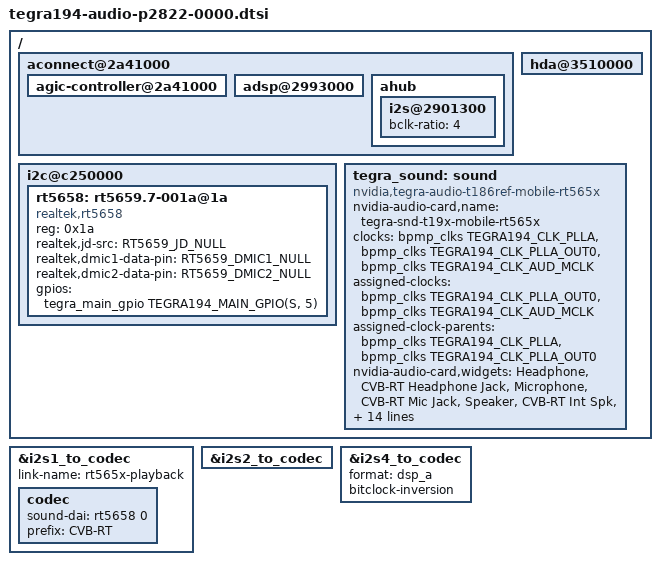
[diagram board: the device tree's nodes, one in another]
/*
 * Copyright (c) 2017-2020, NVIDIA CORPORATION.  All rights reserved.
 *
 * This program is free software; you can redistribute it and/or modify it
 * under the terms and conditions of the GNU General Public License,
 * version 2, as published by the Free Software Foundation.
 *
 * This program is distributed in the hope it will be useful, but WITHOUT
 * ANY WARRANTY; without even the implied warranty of MERCHANTABILITY or
 * FITNESS FOR A PARTICULAR PURPOSE.  See the GNU General Public License for
 * more details.
 *
 * You should have received a copy of the GNU General Public License
 * along with this program.  If not, see <http://www.gnu.org/licenses/>.
 */

/*
 * T194 p2822-0000 audio common DTSI file.
 */

#include <audio/tegra-platforms-audio-dai-links.dtsi>
#include <audio/tegra186-audio-dai-links.dtsi>
#include <dt-bindings/gpio/tegra194-gpio.h>
#include <dt-bindings/sound/rt5659.h>

/ {

	aconnect@2a41000 {
		status = "okay";

		agic-controller@2a41000 {
			status = "okay";
		};

		adsp@2993000 {
			status = "okay";
		};
	};

	i2c@c250000 {
		rt5658: rt5659.7-001a@1a {
			compatible = "realtek,rt5658";
			reg = <0x1a>;

			realtek,jd-src = <RT5659_JD_NULL>;
			realtek,dmic1-data-pin = <RT5659_DMIC1_NULL>;
			realtek,dmic2-data-pin = <RT5659_DMIC2_NULL>;

			gpios = <&tegra_main_gpio TEGRA194_MAIN_GPIO(S, 5) 0>;
			#sound-dai-cells = <1>;

			status = "okay";
		};
	};

	/* Default for all I2S is long fsync width(31) */
	aconnect@2a41000 {
		ahub {
			/* I2S4 in Short frame sync for BT SCO */
			i2s@2901300 {
				bclk-ratio = <4>;
			};
		};
	};

	hda@3510000 {
		status = "okay";
	};

	tegra_sound: sound {
		status = "okay";
		compatible = "nvidia,tegra-audio-t186ref-mobile-rt565x";
		nvidia-audio-card,name = "tegra-snd-t19x-mobile-rt565x";
		clocks = <&bpmp_clks TEGRA194_CLK_PLLA>,
			 <&bpmp_clks TEGRA194_CLK_PLLA_OUT0>,
			 <&bpmp_clks TEGRA194_CLK_AUD_MCLK>;
		clock-names = "pll_a", "pll_a_out0", "extern1";
		assigned-clocks = <&bpmp_clks TEGRA194_CLK_PLLA_OUT0>,
				  <&bpmp_clks TEGRA194_CLK_AUD_MCLK>;
		assigned-clock-parents = <&bpmp_clks TEGRA194_CLK_PLLA>,
					 <&bpmp_clks TEGRA194_CLK_PLLA_OUT0>;

		nvidia-audio-card,widgets =
			"Headphone",	"CVB-RT Headphone Jack",
			"Microphone",	"CVB-RT Mic Jack",
			"Speaker",	"CVB-RT Int Spk",
			"Microphone",	"CVB-RT Int Mic";

		nvidia-audio-card,routing =
			"CVB-RT Headphone Jack",     "CVB-RT HPO L Playback",
			"CVB-RT Headphone Jack",     "CVB-RT HPO R Playback",
			"CVB-RT IN1P",               "CVB-RT Mic Jack",
			"CVB-RT IN2P",               "CVB-RT Mic Jack",
			"CVB-RT Int Spk",            "CVB-RT SPO Playback",
			"CVB-RT DMIC L1",            "CVB-RT Int Mic",
			"CVB-RT DMIC L2",            "CVB-RT Int Mic",
			"CVB-RT DMIC R1",            "CVB-RT Int Mic",
			"CVB-RT DMIC R2",            "CVB-RT Int Mic";

		nvidia-audio-card,mclk-fs = <256>;
	};
};

/*
 * Default config for all I2S dai links are
 * format = "i2s", bitclock-slave, frame-slave,
 * bitclock-noninversion, frame-noninversion,
 * Any change from default needs override on
 * platform specific files.
 */

/* Override with Codec entries */
&i2s1_to_codec {
	link-name = "rt565x-playback";
	codec {
		sound-dai = <&rt5658 0>;
		prefix = "CVB-RT";
	};
};

hdr40_snd_link_i2s: &i2s2_to_codec { };

/* Override with BT SCO entries */
&i2s4_to_codec {
	format = "dsp_a";
	bitclock-inversion;
};
